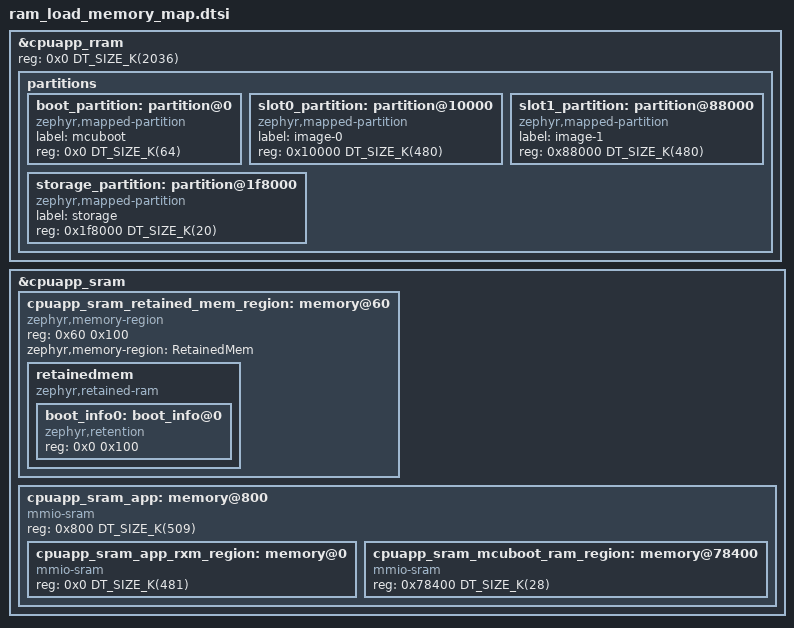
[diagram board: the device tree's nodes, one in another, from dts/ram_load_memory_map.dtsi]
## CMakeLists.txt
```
#
# Copyright (c) 2026 Nordic Semiconductor ASA
#
# SPDX-License-Identifier: LicenseRef-Nordic-5-Clause
#

cmake_minimum_required(VERSION 3.20.0)

find_package(Zephyr REQUIRED HINTS $ENV{ZEPHYR_BASE})
project(NONE)

FILE(GLOB app_sources src/*.c)
target_sources(app PRIVATE ${app_sources})
target_link_libraries(app PRIVATE MCUBOOT_BOOTUTIL)
```

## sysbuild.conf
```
#
# Copyright (c) 2026 Nordic Semiconductor ASA
#
# SPDX-License-Identifier: LicenseRef-Nordic-5-Clause
#

SB_CONFIG_BOOTLOADER_MCUBOOT=y
# No UICR/BOOTCONF programming needed; the test covers only MPC00.
SB_CONFIG_MCUBOOT_BOOTCONF_LOCK_WRITES=n
```

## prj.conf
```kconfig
#
# Copyright (c) 2026 Nordic Semiconductor ASA
#
# SPDX-License-Identifier: LicenseRef-Nordic-5-Clause
#
CONFIG_ZTEST=y
CONFIG_ZTEST_FATAL_HOOK=y
CONFIG_NRFX_RRAMC=y
# The test writes RRAM directly; without this the Zephyr MPU faults before MPC00 is reached.
CONFIG_MPU_ALLOW_FLASH_WRITE=y
CONFIG_MCUBOOT_BOOTUTIL_LIB=y
```

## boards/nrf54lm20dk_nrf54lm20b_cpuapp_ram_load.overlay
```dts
/*
 * Copyright (c) 2026 Nordic Semiconductor ASA
 *
 * SPDX-License-Identifier: LicenseRef-Nordic-5-Clause
 */

#include "../dts/ram_load_memory_map.dtsi"

/ {
	chosen {
		zephyr,bootloader-info = &boot_info0;
		mcuboot,image-ram = &cpuapp_sram_app_rxm_region;
	};
};
```

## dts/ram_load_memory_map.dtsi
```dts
/*
 * Copyright (c) 2026 Nordic Semiconductor ASA
 *
 * SPDX-License-Identifier: LicenseRef-Nordic-5-Clause
 */

&cpuapp_rram {
	/* Application does not use cpuflpr core. Assign whole RRAM to cpuapp. */
	reg = <0x0 DT_SIZE_K(2036)>;

	/* Redefine the "partitions" DTS node. */
	/delete-node/ partitions;

	/* All MPC-covered partitions are aligned to the 4 kB MPC granularity. */
	partitions {
		ranges;
		#address-cells = <1>;
		#size-cells = <1>;

		/* Significantly increase the size of the MCUboot partition to make it fit
		 * for the LLVM configuration variant.
		 */
		boot_partition: partition@0 {
			compatible = "zephyr,mapped-partition";
			label = "mcuboot";
			reg = <0x0 DT_SIZE_K(64)>;
		};

		slot0_partition: partition@10000 {
			compatible = "zephyr,mapped-partition";
			label = "image-0";
			reg = <0x10000 DT_SIZE_K(480)>;
		};

		slot1_partition: partition@88000 {
			compatible = "zephyr,mapped-partition";
			label = "image-1";
			reg = <0x88000 DT_SIZE_K(480)>;
		};

		/* Gap from 100000 to 1f8000 (992 kB) */

		storage_partition: partition@1f8000 {
			compatible = "zephyr,mapped-partition";
			label = "storage";
			reg = <0x1f8000 DT_SIZE_K(20)>;
		};
	};
};

/* Remove the DTS node with the "cpuapp_sram_app" label to redefine the RAM layout.
 * The parent "cpuapp_sram" DTS node is kept, and the "kmu_push_area" DTS node from
 * the SoC devicetree keeps the beginning of the physical RAM reserved for the KMU.
 */
/delete-node/ &cpuapp_sram_app;

&cpuapp_sram {
	/* SRAM region that is shared by both the MCUboot image and the application code.
	 * Currently, it is used to share the image metadata between the bootloader and
	 * the application. This region is retained across reboots only if the
	 * CONFIG_RETAINED_MEM_NRF_RAM_CTRL Kconfig option is enabled.
	 */
	cpuapp_sram_retained_mem_region: memory@60 {
		compatible = "zephyr,memory-region", "mmio-sram";
		reg = <0x60 0x100>;
		zephyr,memory-region = "RetainedMem";
		status = "okay";

		retainedmem {
			compatible = "zephyr,retained-ram";
			status = "okay";
			#address-cells = <1>;
			#size-cells = <1>;

			boot_info0: boot_info@0 {
				compatible = "zephyr,retention";
				status = "okay";
				reg = <0x0 0x100>;
			};
		};
	};

	/* Redefine the "cpuapp_sram_app" DTS node and specify the necessary RAM subregions
	 * that can be used to configure the MCUboot image. The board devicetree assigns this
	 * DTS node to the application image as its chosen SRAM DTS node. Additionally, the
	 * start address of this DTS node must be aligned with 0x800 bytes due to the Zephyr
	 * build system requirements. The build system places the executable ROM section
	 * (code) at the beginning of this region and the RAM section (data) right after
	 * the ROM section.
	 */
	cpuapp_sram_app: memory@800 {
		compatible = "mmio-sram";
		reg = <0x800 DT_SIZE_K(509)>;
		#address-cells = <1>;
		#size-cells = <1>;
		ranges = <0x0 0x800 DT_SIZE_K(509)>;

		/* SRAM region for storing the ROM section (code) and RAM section (data) of
		 * the application image. The RAM section of the application image may also
		 * partially or fully fill the subsequent SRAM region called
		 * "cpuapp_sram_mcuboot_ram_region", but its ROM section must never enter
		 * this region. This ROM section defines the memory space where MCUboot
		 * copies the application image. If this copied data overlaps with the
		 * MCUboot RAM region, MCUboot may encounter runtime errors. It is
		 * recommended to use this DTS node for configuration of the executable
		 * SRAM region in the MCUboot image. Point /chosen/mcuboot,image-ram at
		 * this node in both MCUboot and application images so
		 * CONFIG_BOOT_IMAGE_EXECUTABLE_RAM_START/SIZE default from devicetree.
		 */
		cpuapp_sram_app_rxm_region: memory@0 {
			compatible = "mmio-sram";
			reg = <0x0 DT_SIZE_K(481)>;
			#address-cells = <1>;
			#size-cells = <1>;
			ranges = <0x0 0x0 DT_SIZE_K(481)>;
		};

		/* SRAM region for storing the RAM section (data) of the MCUboot image. The
		 * RAM section of the application image may also partially or fully fill
		 * this region, but the ROM section of the application image must never
		 * enter this region. This ROM section defines the memory space where
		 * MCUboot copies the application image. If this copied data overlaps with
		 * the MCUboot RAM region, MCUboot may encounter runtime errors. This DTS
		 * node must be assigned to the MCUboot image as its chosen SRAM DTS node.
		 */
		cpuapp_sram_mcuboot_ram_region: memory@78400 {
			compatible = "mmio-sram";
			reg = <0x78400 DT_SIZE_K(28)>;
			#address-cells = <1>;
			#size-cells = <1>;
			ranges = <0x0 0x78400 DT_SIZE_K(28)>;
		};
	};
};
```

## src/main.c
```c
/*
 * Copyright (c) 2026 Nordic Semiconductor ASA
 *
 * SPDX-License-Identifier: LicenseRef-Nordic-5-Clause
 */

#include <zephyr/ztest.h>
#include <zephyr/ztest_error_hook.h>
#include <zephyr/devicetree.h>
#include <zephyr/sys/util.h>
#include <hal/nrf_mpc.h>
#include <hal/nrf_rramc.h>
#include <nrfx_rramc.h>
#include <bootutil/image.h>
#include <bl_mpc.h>

/* General-purpose overrides plus the access-blocking override. */
#define MPC_OVERRIDES_CHECKED (BL_MPC_REGION_COUNT_MAX + 1)

#define PART_START(label) DT_PARTITION_ADDR(DT_NODELABEL(label))
#define PART_END(label)	  (PART_START(label) + DT_REG_SIZE(DT_NODELABEL(label)))

#define PERM_R	(NRF_MPC_PERM_READ_MASK | NRF_MPC_PERM_SECURE_MASK)
#define PERM_RX (PERM_R | NRF_MPC_PERM_EXECUTE_MASK)
#define PERM_RW (PERM_R | NRF_MPC_PERM_WRITE_MASK)

struct expected_override {
	uint32_t start;
	uint32_t end;
	uint32_t perm;
};

static uint32_t slot0_code_end(void)
{
	const struct image_header *hdr = (const struct image_header *)PART_START(slot0_partition);

	uint32_t code_end;

	zassert_equal(hdr->ih_magic, IMAGE_MAGIC, "No image header at slot0");

	code_end = ROUND_UP(PART_START(slot0_partition) + hdr->ih_hdr_size + hdr->ih_img_size,
			    BL_MPC_GRANULARITY_BYTES);
#if defined(CONFIG_MCUBOOT_BOOTLOADER_MODE_RAM_LOAD)
	code_end = MIN(code_end, PART_END(slot0_partition) - BL_MPC_GRANULARITY_BYTES);
#endif
	return code_end;
}

static void perm_print(uint32_t perm, char *str)
{
	str[0] = (perm & NRF_MPC_PERM_READ_MASK) ? 'R' : '-';
	str[1] = (perm & NRF_MPC_PERM_WRITE_MASK) ? 'W' : '-';
	str[2] = (perm & NRF_MPC_PERM_EXECUTE_MASK) ? 'X' : '-';
	str[3] = '\0';
}

static void rram_word_write_back(uint32_t address)
{
	nrf_rramc_word_write(address, *(volatile uint32_t *)address);
	__DSB();
}

void ztest_post_fatal_error_hook(unsigned int reason, const struct arch_esf *esf)
{
	ARG_UNUSED(esf);

	printk("Expected fault caught, reason %u\n", reason);
	nrfx_rramc_write_enable_set(false, 0);
	ztest_test_pass();
}

ZTEST(bl_mpc_mcuboot, test_overrides_locked)
{
	uint32_t code_end = slot0_code_end();
	const struct expected_override expected[] = {
#if defined(CONFIG_MCUBOOT_BOOTLOADER_MODE_RAM_LOAD)
		{PART_START(slot0_partition), code_end, PERM_R},
		{code_end, PART_END(slot1_partition), PERM_RW},
		{PART_START(storage_partition), PART_END(storage_partition), PERM_RW},
#else
		{PART_START(slot0_partition), code_end, PERM_RX},
		{code_end, PART_END(storage_partition), PERM_RW},
#endif
	};

	for (uint8_t i = 0; i < MPC_OVERRIDES_CHECKED; i++) {
		nrf_mpc_override_config_t config = nrf_mpc_override_config_get(NRF_MPC00, i);

		zassert_true(config.lock, "Override %u not locked", i);

		if (i >= ARRAY_SIZE(expected)) {
			zassert_false(config.enable, "Override %u enabled", i);
			continue;
		}

		uint32_t start = nrf_mpc_override_startaddr_get(NRF_MPC00, i);
		uint32_t end = nrf_mpc_override_endaddr_get(NRF_MPC00, i);
		uint32_t perm = nrf_mpc_override_perm_get(NRF_MPC00, i);
		char perm_str[4];

		perm_print(perm, perm_str);
		printk("MPC override %u start 0x%08x end 0x%08x perm %s locked\n", i, start, end,
		       perm_str);

		zassert_true(config.enable, "Override %u disabled", i);
		zassert_equal(start, expected[i].start, "Override %u start", i);
		zassert_equal(end, expected[i].end, "Override %u end", i);
		zassert_equal(perm, expected[i].perm, "Override %u perm", i);
	}

	printk("MPC overrides %u-%u locked disabled\n", (unsigned int)ARRAY_SIZE(expected),
	       MPC_OVERRIDES_CHECKED - 1);
}

ZTEST(bl_mpc_mcuboot, test_primary_slot_write_blocked)
{
	nrfx_rramc_write_enable_set(true, 0);
	nrf_mpc_event_clear(NRF_MPC00, NRF_MPC_EVENT_MEMACCERR);
	ztest_set_fault_valid(true);

	rram_word_write_back(PART_START(slot0_partition));

	ztest_set_fault_valid(false);
	nrfx_rramc_write_enable_set(false, 0);
	zassert_true(nrf_mpc_event_check(NRF_MPC00, NRF_MPC_EVENT_MEMACCERR),
		     "Write to the primary slot code was not blocked");
}

ZTEST(bl_mpc_mcuboot, test_rw_regions_writable)
{
	nrfx_rramc_write_enable_set(true, 0);

	rram_word_write_back(slot0_code_end());
	rram_word_write_back(PART_START(slot1_partition));
	rram_word_write_back(PART_START(storage_partition));

	nrfx_rramc_write_enable_set(false, 0);
}

ZTEST_SUITE(bl_mpc_mcuboot, NULL, NULL, NULL, NULL, NULL);
```
